VERSION "All_Common"

NS_ :

BS_:

BU_: PCM SRS UNKNOWN

BO_ 57 SRS_0x039: 3 SRS
 SG_ SRS_MONITOR_INHIBIT : 0|1@1+ (1,0) [0|1] ""  PCM
 SG_ PRIMARY_WARNING_LATCH_CONTRIBUTION : 1|1@1+ (1,0) [0|1] ""  PCM
 SG_ CURRENT_B2800_49_RECORD_FAILURE : 2|1@1+ (1,0) [0|1] ""  PCM
 SG_ TIMED_NOTIFICATION_9 : 3|1@1+ (1,0) [0|1] ""  PCM
 SG_ TIMED_NOTIFICATION_7 : 4|1@1+ (1,0) [0|1] ""  PCM
 SG_ TIMED_NOTIFICATION_6 : 5|1@1+ (1,0) [0|1] ""  PCM
 SG_ TIMED_NOTIFICATION_5 : 6|1@1+ (1,0) [0|1] ""  PCM
 SG_ TIMED_NOTIFICATION_4 : 7|1@1+ (1,0) [0|1] ""  PCM
 SG_ TIMED_NOTIFICATION_3 : 8|1@1+ (1,0) [0|1] ""  PCM
 SG_ TIMED_NOTIFICATION_2 : 9|1@1+ (1,0) [0|1] ""  PCM
 SG_ TIMED_NOTIFICATION_1 : 10|1@1+ (1,0) [0|1] ""  PCM
 SG_ TIMED_NOTIFICATION_0 : 11|1@1+ (1,0) [0|1] ""  PCM
 SG_ TIMED_NOTIFICATION_8 : 12|1@1+ (1,0) [0|1] ""  PCM
 SG_ UNKNOWN_1 : 13|2@1+ (1,0) [0|3] ""  PCM
 SG_ SRS_WARNING_STARTUP_AND_PATTERN_STATE : 15|1@1+ (1,0) [0|1] ""  PCM
 SG_ CHECKSUM : 16|4@1+ (1,0) [0|15] ""  PCM
 SG_ COUNTER : 20|2@1+ (1,0) [0|3] ""  PCM
 SG_ OPTIONAL_STATUS_MASK_ACTIVE : 22|1@1+ (1,0) [0|1] ""  PCM
 SG_ OPTIONAL_WARNING_MASK_ACTIVE : 23|1@1+ (1,0) [0|1] ""  PCM

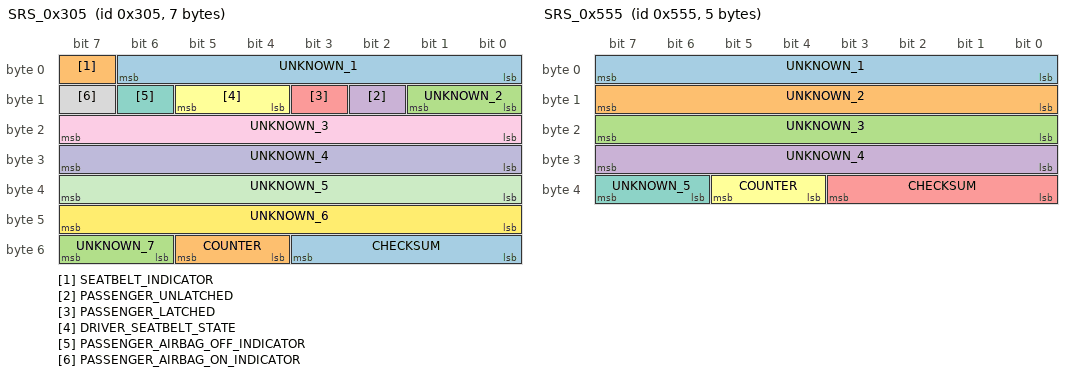
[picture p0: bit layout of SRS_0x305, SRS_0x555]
BO_ 773 SRS_0x305: 7 SRS
 SG_ UNKNOWN_1 : 0|7@1+ (1,0) [0|127] ""  PCM
 SG_ SEATBELT_INDICATOR : 7|1@1+ (1,0) [0|1] ""  PCM
 SG_ UNKNOWN_2 : 8|2@1+ (1,0) [0|3] ""  PCM
 SG_ PASSENGER_UNLATCHED : 10|1@1+ (1,0) [0|1] ""  PCM
 SG_ PASSENGER_LATCHED : 11|1@1+ (1,0) [0|1] ""  PCM
 SG_ DRIVER_SEATBELT_STATE : 12|2@1+ (1,0) [0|3] ""  PCM
 SG_ PASSENGER_AIRBAG_OFF_INDICATOR : 14|1@1+ (1,0) [0|1] ""  PCM
 SG_ PASSENGER_AIRBAG_ON_INDICATOR : 15|1@1+ (1,0) [0|1] ""  PCM
 SG_ UNKNOWN_3 : 16|8@1+ (1,0) [0|255] ""  PCM
 SG_ UNKNOWN_4 : 24|8@1+ (1,0) [0|255] ""  PCM
 SG_ UNKNOWN_5 : 32|8@1+ (1,0) [0|255] ""  PCM
 SG_ UNKNOWN_6 : 40|8@1+ (1,0) [0|255] ""  PCM
 SG_ CHECKSUM : 48|4@1+ (1,0) [0|15] ""  PCM
 SG_ COUNTER : 52|2@1+ (1,0) [0|3] ""  PCM
 SG_ UNKNOWN_7 : 54|2@1+ (1,0) [0|3] ""  PCM

BO_ 1365 SRS_0x555: 5 SRS
 SG_ UNKNOWN_1 : 0|8@1+ (1,0) [0|255] ""  UNKNOWN
 SG_ UNKNOWN_2 : 8|8@1+ (1,0) [0|255] ""  UNKNOWN
 SG_ UNKNOWN_3 : 16|8@1+ (1,0) [0|255] ""  UNKNOWN
 SG_ UNKNOWN_4 : 24|8@1+ (1,0) [0|255] ""  UNKNOWN
 SG_ CHECKSUM : 32|4@1+ (1,0) [0|15] ""  UNKNOWN
 SG_ COUNTER : 36|2@1+ (1,0) [0|3] ""  UNKNOWN
 SG_ UNKNOWN_5 : 38|2@1+ (1,0) [0|3] ""  UNKNOWN
